# HC32F558 register map
File version: 1.0
CPU: CM4 r0p1, little endian, MPU, FPU, 4 interrupt priority bits
Registers are 32-bit, read-write, reset 0x0 unless marked. A register's access mark holds for its fields unless they carry their own. Offsets are from the block's base; [hi:lo] are bit positions; {n}, {i} and the like mark numbered series.

## DSOGI_PLL
Base 0x40020C00
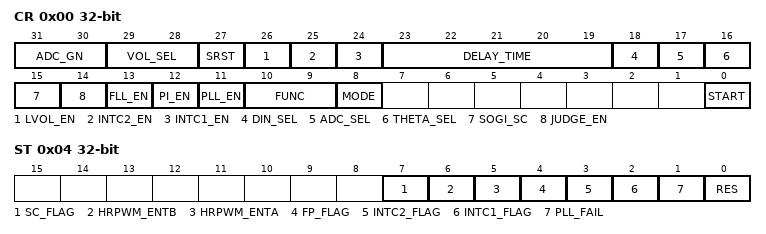
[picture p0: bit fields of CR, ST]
0x00 CR
  [31:30] ADC_GN, [29:28] VOL_SEL, [27] SRST, [26] LVOL_EN, [25] INTC2_EN, [24] INTC1_EN, [23:19] DELAY_TIME, [18] DIN_SEL, [17] ADC_SEL, [16] THETA_SEL, [15] SOGI_SC, [14] JUDGE_EN, [13] FLL_EN, [12] PI_EN, [11] PLL_EN, [10:9] FUNC, [8] MODE, [0] START
0x04 ST
  [7] SC_FLAG, [6] HRPWM_ENTB, [5] HRPWM_ENTA, [4] FP_FLAG, [3] INTC2_FLAG, [2] INTC1_FLAG, [1] PLL_FAIL, [0] RES
0x08 CLARKK
0x0C CLARKAS
0x10 CLARKBS
0x14 CLARKCS
0x18 CLARKDS
0x1C CLARKQS
0x20 CLARKFLTA
0x24 CLARKFLTB
0x28 CLARKFLTC
0x2C K
0x30 DK
0x34 QK
0x38 TS
0x3C FLLK
0x40 FREBASE
0x44 MAX
0x48 MIN
0x4C DS
0x50 QS
0x54 W
0x58 ALPHADV
0x5C ALPHAQV
0x60 BETADV
0x64 BETAQV
0x68 VGRIDPDS
0x6C VGRIDPQS
0x70 VGRIDNDS
0x74 VGRIDNQS
0x78 PARKDS
0x7C PARKQS
0x80 PARKTHETA
0x84 PARKDE
0x88 PARKQE
0x8C PARKSIN
0x90 PARKCOS
0x94 PLLK
0x98 PLLKP
0x9C PLLKITS
0xA0 PLLMAX
0xA4 PLLMIN
0xA8 PLLFINISHERRTH
{0xA8+4i} PLLTHETACMP{i} (i=1..4)
0xBC PLLVGCMP
0xC0 PLLTHETASTEP
0xC4 PLLDIN
0xC8 PLLW
0xCC PLLUP
0xD0 PLLUI
0xD4 PLLPI
0xD8 PLLTHETA
0xDC PLLTHETA_PI
0xE0 PLLFREQ
0xE4 PLLDINFLT
0xE8 PLLSIN
0xEC PLLCOS

## EFM
Base 0x40010400
0x00 FAPRT
  [15:0] FAPRT
0x04 KEY1
0x08 KEY2
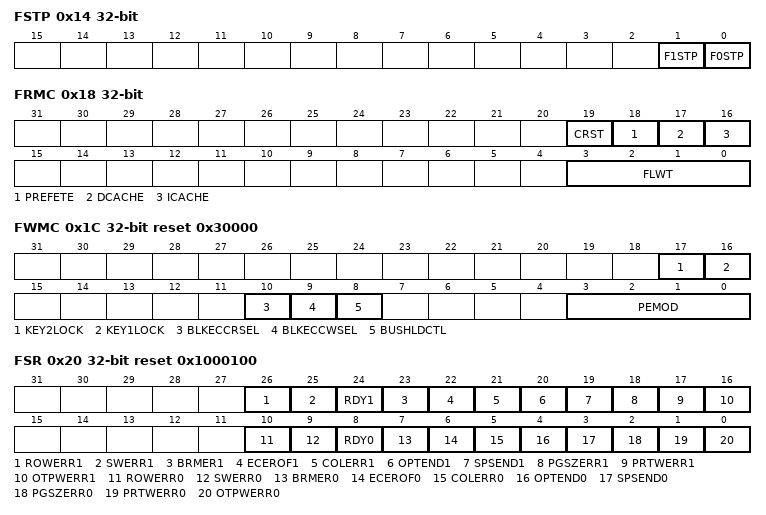
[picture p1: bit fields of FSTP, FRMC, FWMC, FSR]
0x14 FSTP
  [1] F1STP, [0] F0STP
0x18 FRMC
  [19] CRST, [18] PREFETE, [17] DCACHE, [16] ICACHE, [3:0] FLWT
0x1C FWMC reset 0x30000
  [17] KEY2LOCK, [16] KEY1LOCK, [10] BLKECCRSEL, [9] BLKECCWSEL, [8] BUSHLDCTL, [3:0] PEMOD
0x20 FSR ro reset 0x1000100
  [26] ROWERR1, [25] SWERR1, [24] RDY1, [23] BRMER1, [22] ECEROF1, [21] COLERR1, [20] OPTEND1, [19] SPSEND1, [18] PGSZERR1, [17] PRTWERR1, [16] OTPWERR1, [10] ROWERR0, [9] SWERR0, [8] RDY0, [7] BRMER0, [6] ECEROF0, [5] COLERR0, [4] OPTEND0, [3] SPSEND0, [2] PGSZERR0, [1] PRTWERR0, [0] OTPWERR0
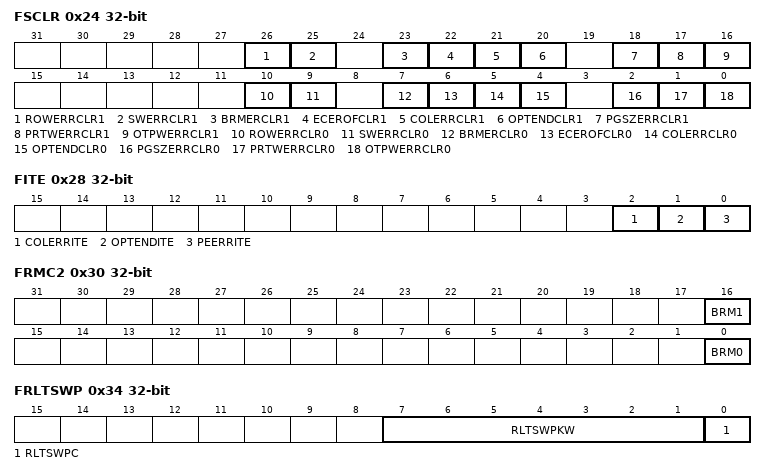
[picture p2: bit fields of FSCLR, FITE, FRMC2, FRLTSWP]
0x24 FSCLR
  [26] ROWERRCLR1, [25] SWERRCLR1, [23] BRMERCLR1, [22] ECEROFCLR1, [21] COLERRCLR1, [20] OPTENDCLR1, [18] PGSZERRCLR1, [17] PRTWERRCLR1, [16] OTPWERRCLR1, [10] ROWERRCLR0, [9] SWERRCLR0, [7] BRMERCLR0, [6] ECEROFCLR0, [5] COLERRCLR0, [4] OPTENDCLR0, [2] PGSZERRCLR0, [1] PRTWERRCLR0, [0] OTPWERRCLR0
0x28 FITE
  [2] COLERRITE, [1] OPTENDITE, [0] PEERRITE
0x2C FSWP ro
  [0] FSWP
0x30 FRMC2
  [16] BRM1, [0] BRM0
0x34 FRLTSWP
  [7:1] RLTSWPKW, [0] RLTSWPC
0x40 CHIPID ro reset 0x58480558
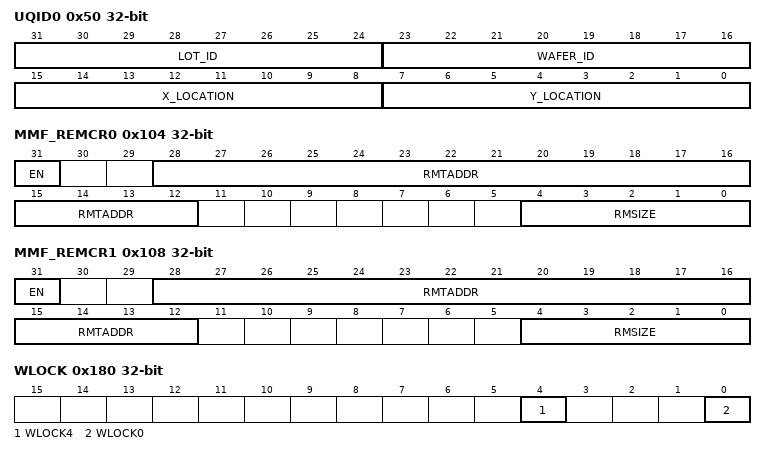
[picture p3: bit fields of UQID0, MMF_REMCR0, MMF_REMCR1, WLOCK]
0x50 UQID0 ro
  [31:24] LOT_ID, [23:16] WAFER_ID, [15:8] X_LOCATION, [7:0] Y_LOCATION
0x54 UQID1 ro
0x58 UQID2 ro
  [7:0] LOT_ID
0x100 MMF_REMPRT
  [15:0] MMF_REMPRT
0x104 MMF_REMCR0
  [31] EN, [28:12] RMTADDR, [4:0] RMSIZE
0x108 MMF_REMCR1
  [31] EN, [28:12] RMTADDR, [4:0] RMSIZE
0x180 WLOCK
  [4] WLOCK4, [0] WLOCK0
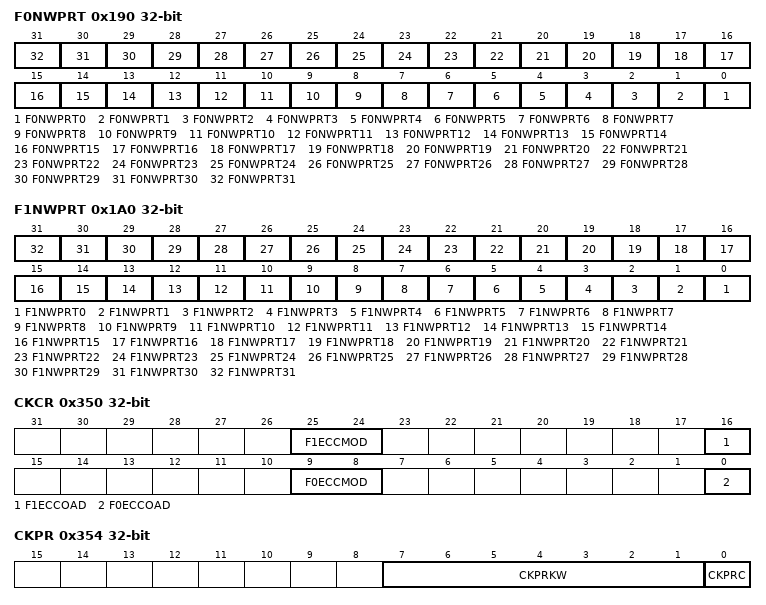
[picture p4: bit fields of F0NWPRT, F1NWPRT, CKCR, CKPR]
0x190 F0NWPRT
  [n] F0NWPRT{n} (n=0..31)
0x1A0 F1NWPRT
  [n] F1NWPRT{n} (n=0..31)
0x350 CKCR
  [25:24] F1ECCMOD, [16] F1ECCOAD, [9:8] F0ECCMOD, [0] F0ECCOAD
0x354 CKPR
  [7:1] CKPRKW, [0] CKPRC
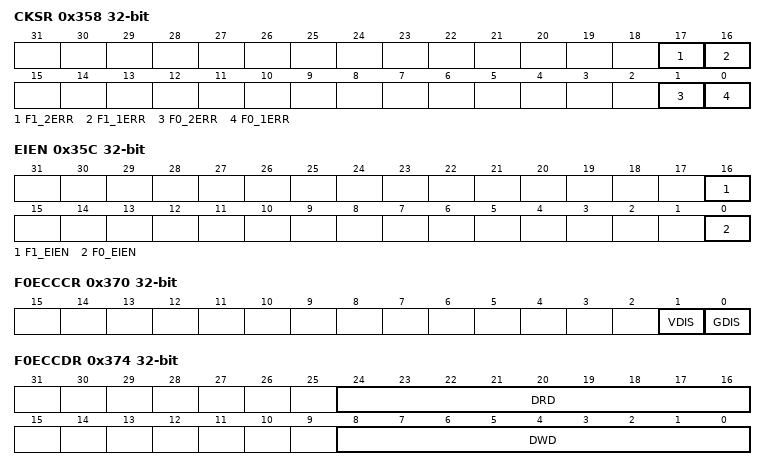
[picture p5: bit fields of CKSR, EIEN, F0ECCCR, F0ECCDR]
0x358 CKSR
  [17] F1_2ERR, [16] F1_1ERR, [1] F0_2ERR, [0] F0_1ERR
0x35C EIEN
  [16] F1_EIEN, [0] F0_EIEN
0x370 F0ECCCR
  [1] VDIS, [0] GDIS
0x374 F0ECCDR
  [24:16] DRD ro, [8:0] DWD
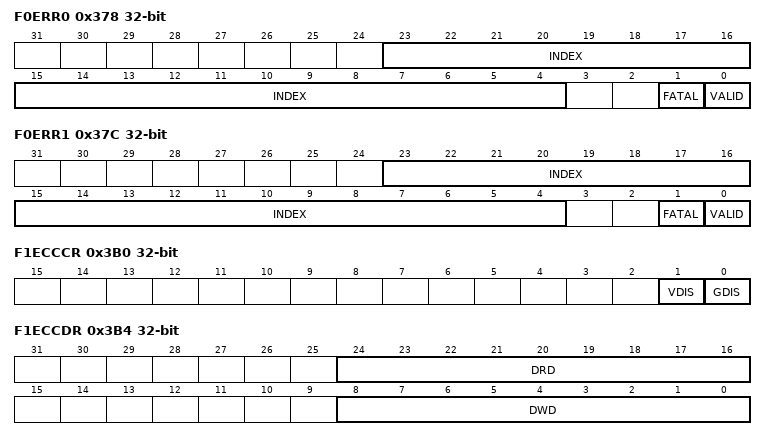
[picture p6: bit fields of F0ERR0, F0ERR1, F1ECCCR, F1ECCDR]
0x378 F0ERR0
  [23:4] INDEX ro, [1] FATAL, [0] VALID
0x37C F0ERR1
  [23:4] INDEX ro, [1] FATAL, [0] VALID
{0x380+4i} F0EIR{i} (i=0..4)
0x3B0 F1ECCCR
  [1] VDIS, [0] GDIS
0x3B4 F1ECCDR
  [24:16] DRD ro, [8:0] DWD
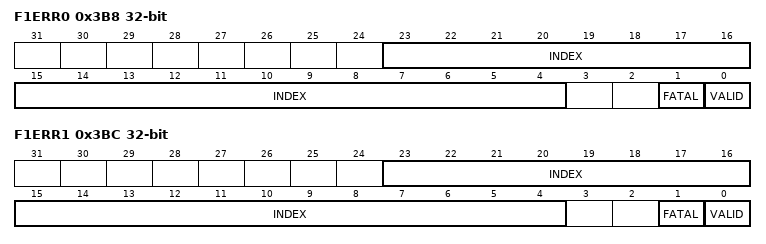
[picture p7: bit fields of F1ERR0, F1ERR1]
0x3B8 F1ERR0
  [23:4] INDEX ro, [1] FATAL, [0] VALID
0x3BC F1ERR1
  [23:4] INDEX ro, [1] FATAL, [0] VALID
{0x3C0+4i} F1EIR{i} (i=0..4)

## EMB0 — desc EMB
Base 0x40038800
Same registers: EMB1 0x40038840, EMB2 0x40038880, EMB3 0x400388C0, EMB4 0x40038900, EMB5 0x40038940
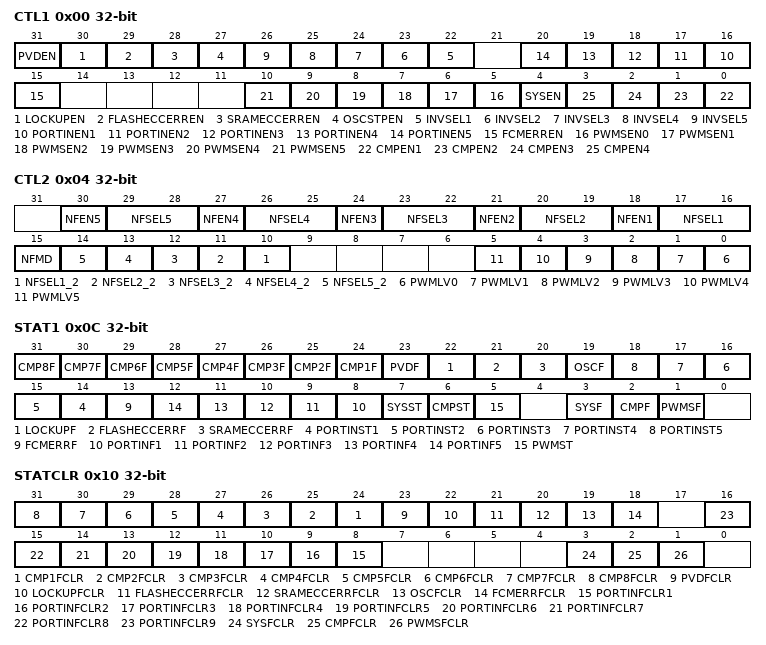
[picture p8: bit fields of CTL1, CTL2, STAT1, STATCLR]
0x00 CTL1
  [31] PVDEN, [30] LOCKUPEN, [29] FLASHECCERREN, [28] SRAMECCERREN, [27] OSCSTPEN, [n+21] INVSEL{n} (n=1..5), [n+15] PORTINEN{n} (n=1..5), [15] FCMERREN, [n+5] PWMSEN{n} (n=0..5), [4] SYSEN, [n-1] CMPEN{n} (n=1..4)
0x04 CTL2
  [3n+15] NFEN{n} (n=1..5), [3n+14:3n+13] NFSEL{n} (n=1..5), [15] NFMD, [n+9] NFSEL{n}_2 (n=1..5), [n] PWMLV{n} (n=0..5)
0x08 SOE
  [0] SOE
0x0C STAT1 ro
  [n+23] CMP{n}F (n=1..8), [23] PVDF, [22] LOCKUPF, [21] FLASHECCERRF, [20] SRAMECCERRF, [19] OSCF, [n+13] PORTINST{n} (n=1..5), [13] FCMERRF, [n+7] PORTINF{n} (n=1..5), [7] SYSST, [6] CMPST, [5] PWMST, [3] SYSF, [2] CMPF, [1] PWMSF
0x10 STATCLR wo
  [n+23] CMP{n}FCLR (n=1..8), [23] PVDFCLR, [22] LOCKUPFCLR, [21] FLASHECCERRFCLR, [20] SRAMECCERRFCLR, [19] OSCFCLR, [18] FCMERRFCLR, [n+7] PORTINFCLR{n} (n=1..9), [3] SYSFCLR, [2] CMPFCLR, [1] PWMSFCLR
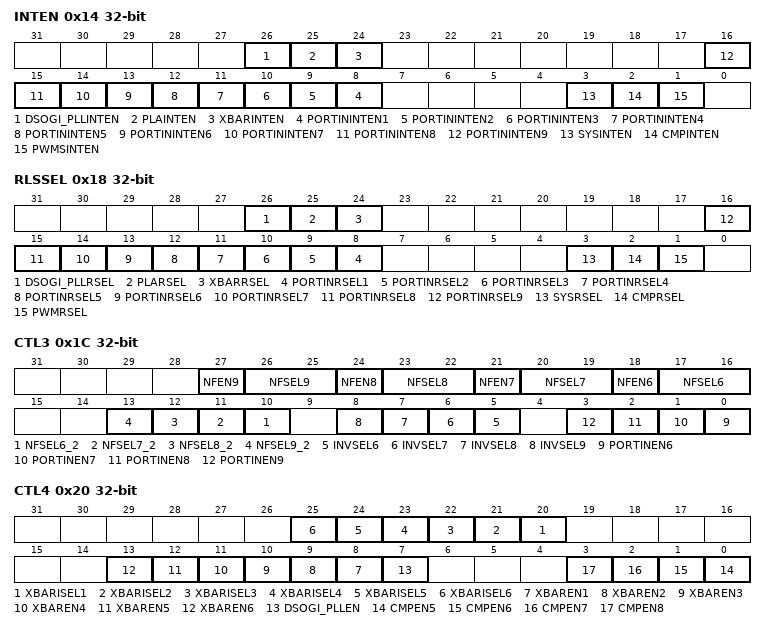
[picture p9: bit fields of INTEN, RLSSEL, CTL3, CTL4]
0x14 INTEN
  [26] DSOGI_PLLINTEN, [25] PLAINTEN, [24] XBARINTEN, [n+7] PORTININTEN{n} (n=1..9), [3] SYSINTEN, [2] CMPINTEN, [1] PWMSINTEN
0x18 RLSSEL
  [26] DSOGI_PLLRSEL, [25] PLARSEL, [24] XBARRSEL, [n+7] PORTINRSEL{n} (n=1..9), [3] SYSRSEL, [2] CMPRSEL, [1] PWMRSEL
0x1C CTL3
  [3n] NFEN{n} (n=6..9), [3n-1:3n-2] NFSEL{n} (n=6..9), [n+4] NFSEL{n}_2 (n=6..9), [n-1] INVSEL{n} (n=6..9), [n-6] PORTINEN{n} (n=6..9)
0x20 CTL4
  [n+19] XBARISEL{n} (n=1..6), [n+7] XBAREN{n} (n=1..6), [7] DSOGI_PLLEN, [n-5] CMPEN{n} (n=5..8)
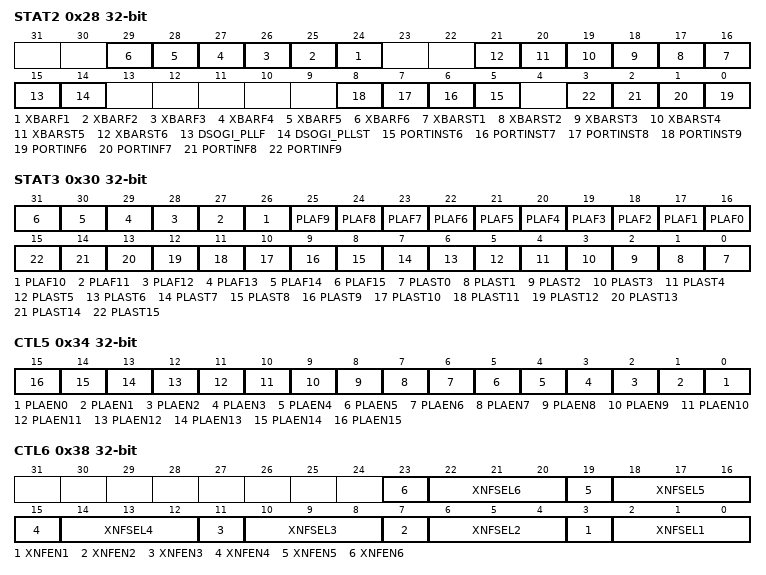
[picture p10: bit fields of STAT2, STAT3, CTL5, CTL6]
0x28 STAT2
  [n+23] XBARF{n} (n=1..6), [n+15] XBARST{n} ro (n=1..6), [15] DSOGI_PLLF, [14] DSOGI_PLLST ro, [n-1] PORTINST{n} ro (n=6..9), [n-6] PORTINF{n} ro (n=6..9)
0x30 STAT3
  [n+16] PLAF{n} (n=0..15), [n] PLAST{n} ro (n=0..15)
0x34 CTL5
  [n] PLAEN{n} (n=0..15)
0x38 CTL6
  [4n-1] XNFEN{n} (n=1..6), [4n-2:4n-4] XNFSEL{n} (n=1..6)
